VERSION ""

NS_ :

BS_:

BU_: SensoricSolutionsOMSRace SensoricSolutionsOMS7

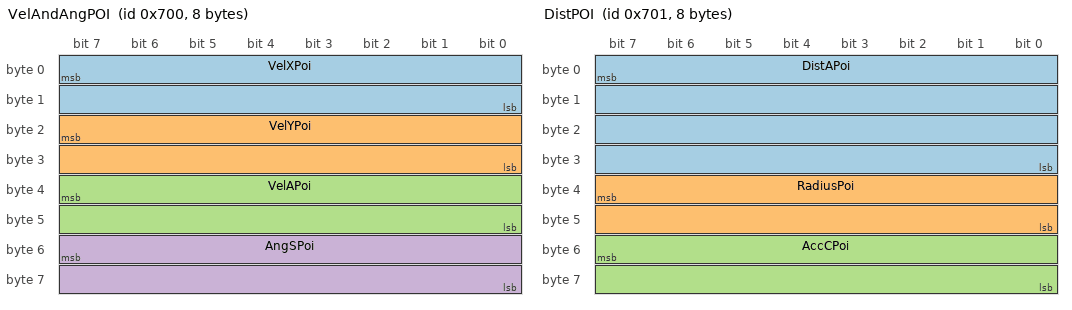
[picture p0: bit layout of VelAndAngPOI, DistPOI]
BO_ 1792 VelAndAngPOI: 8 SensoricSolutionsOMSRace
 SG_ VelXPoi : 7|16@0- (0.02,0) [-450|450] "km/h"  SensoricSolutionsOMSRace
 SG_ VelYPoi : 23|16@0- (0.02,0) [-100|100] "km/h"  SensoricSolutionsOMSRace
 SG_ VelAPoi : 39|16@0- (0.02,0) [0|450] "km/h"  SensoricSolutionsOMSRace
 SG_ AngSPoi : 55|16@0- (0.003,0) [-40|40] "deg"  SensoricSolutionsOMSRace

BO_ 1793 DistPOI: 8 SensoricSolutionsOMSRace
 SG_ DistAPoi : 7|32@0- (0.001,0) [-2000000|2000000] "m"  SensoricSolutionsOMSRace
 SG_ RadiusPoi : 39|16@0- (0.01,0) [-327.68|327.67] "m"  SensoricSolutionsOMSRace
 SG_ AccCPoi : 55|16@0- (0.02,0) [-200|200] "m/s/s"  SensoricSolutionsOMSRace

BO_ 1794 PitchAndRoll: 4 SensoricSolutionsOMSRace
 SG_ Roll : 7|16@0- (0.003,0) [-90|90] "deg"  SensoricSolutionsOMSRace
 SG_ Pitch : 23|16@0- (0.003,0) [-90|90] "deg"  SensoricSolutionsOMSRace

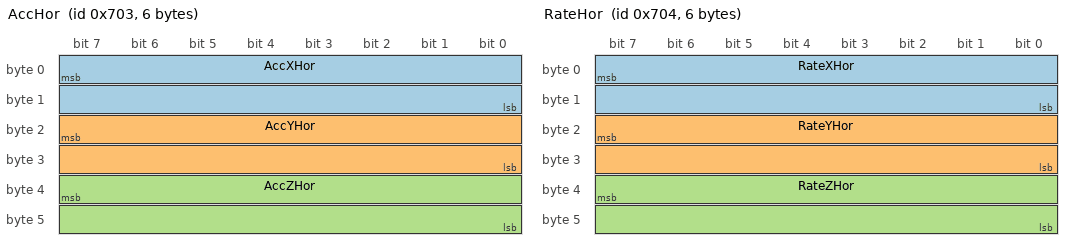
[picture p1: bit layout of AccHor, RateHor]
BO_ 1795 AccHor: 6 SensoricSolutionsOMSRace
 SG_ AccXHor : 7|16@0- (0.02,0) [-200|200] "m/s/s"  SensoricSolutionsOMSRace
 SG_ AccYHor : 23|16@0- (0.02,0) [-200|200] "m/s/s"  SensoricSolutionsOMSRace
 SG_ AccZHor : 39|16@0- (0.02,0) [-200|200] "m/s/s"  SensoricSolutionsOMSRace

BO_ 1796 RateHor: 6 SensoricSolutionsOMSRace
 SG_ RateXHor : 7|16@0- (0.02,0) [-500|500] "deg/s"  SensoricSolutionsOMSRace
 SG_ RateYHor : 23|16@0- (0.02,0) [-500|500] "deg/s"  SensoricSolutionsOMSRace
 SG_ RateZHor : 39|16@0- (0.02,0) [-500|500] "deg/s"  SensoricSolutionsOMSRace

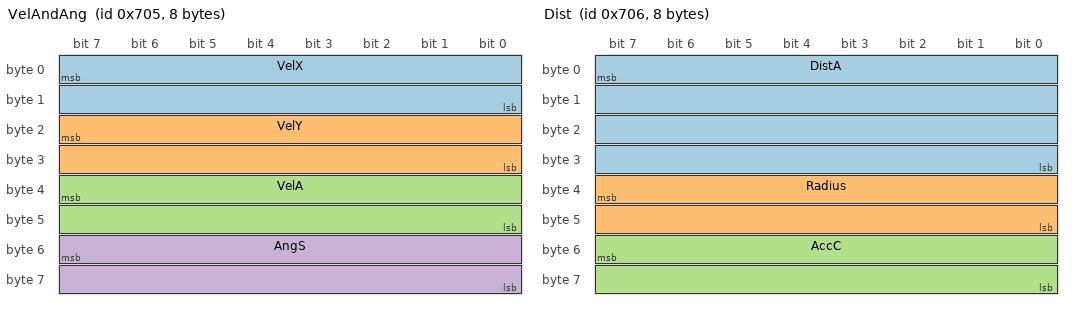
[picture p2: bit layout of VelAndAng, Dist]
BO_ 1797 VelAndAng: 8 SensoricSolutionsOMSRace
 SG_ VelX : 7|16@0- (0.02,0) [-450|450] "km/h"  SensoricSolutionsOMSRace
 SG_ VelY : 23|16@0- (0.02,0) [-100|100] "km/h"  SensoricSolutionsOMSRace
 SG_ VelA : 39|16@0- (0.02,0) [0|450] "km/h"  SensoricSolutionsOMSRace
 SG_ AngS : 55|16@0- (0.003,0) [-40|40] "deg"  SensoricSolutionsOMSRace

BO_ 1798 Dist: 8 SensoricSolutionsOMSRace
 SG_ DistA : 7|32@0- (0.001,0) [-2000000|2000000] "m"  SensoricSolutionsOMSRace
 SG_ Radius : 39|16@0- (0.01,0) [-327.68|327.67] "m"  SensoricSolutionsOMSRace
 SG_ AccC : 55|16@0- (0.02,0) [-200|200] "m/s/s"  SensoricSolutionsOMSRace

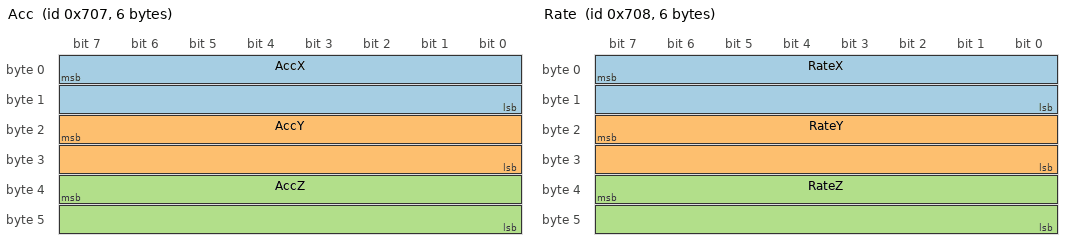
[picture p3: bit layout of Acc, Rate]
BO_ 1799 Acc: 6 SensoricSolutionsOMSRace
 SG_ AccX : 7|16@0- (0.02,0) [-200|200] "m/s/s"  SensoricSolutionsOMSRace
 SG_ AccY : 23|16@0- (0.02,0) [-200|200] "m/s/s"  SensoricSolutionsOMSRace
 SG_ AccZ : 39|16@0- (0.02,0) [-200|200] "m/s/s"  SensoricSolutionsOMSRace

BO_ 1800 Rate: 6 SensoricSolutionsOMSRace
 SG_ RateX : 7|16@0- (0.02,0) [-500|500] "deg/s"  SensoricSolutionsOMSRace
 SG_ RateY : 23|16@0- (0.02,0) [-500|500] "deg/s"  SensoricSolutionsOMSRace
 SG_ RateZ : 39|16@0- (0.02,0) [-500|500] "deg/s"  SensoricSolutionsOMSRace

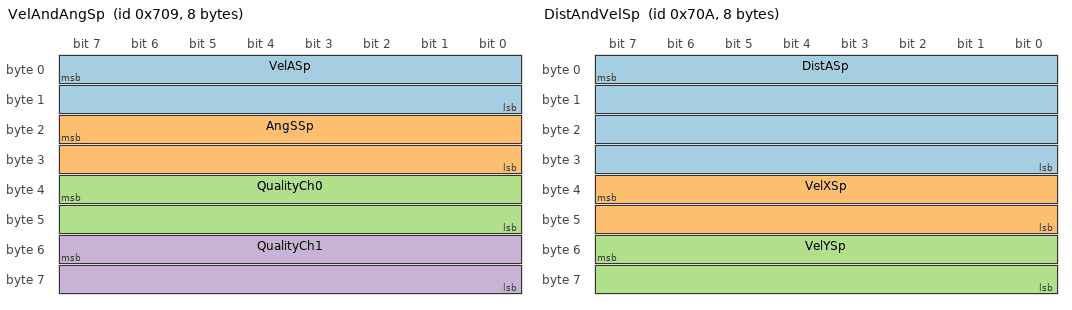
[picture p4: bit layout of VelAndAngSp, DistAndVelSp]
BO_ 1801 VelAndAngSp: 8 SensoricSolutionsOMSRace
 SG_ VelASp : 7|16@0- (0.02,0) [0|450] "km/h"  SensoricSolutionsOMSRace
 SG_ AngSSp : 23|16@0- (0.003,0) [-40|40] "deg"  SensoricSolutionsOMSRace
 SG_ QualityCh0 : 39|16@0+ (1,0) [0|65535] ""  SensoricSolutionsOMSRace
 SG_ QualityCh1 : 55|16@0+ (1,0) [0|65535] ""  SensoricSolutionsOMSRace

BO_ 1802 DistAndVelSp: 8 SensoricSolutionsOMSRace
 SG_ DistASp : 7|32@0- (0.001,0) [-2000000|2000000] "m"  SensoricSolutionsOMSRace
 SG_ VelXSp : 39|16@0- (0.02,0) [-450|450] "km/h"  SensoricSolutionsOMSRace
 SG_ VelYSp : 55|16@0- (0.02,0) [-100|100] "km/h"  SensoricSolutionsOMSRace

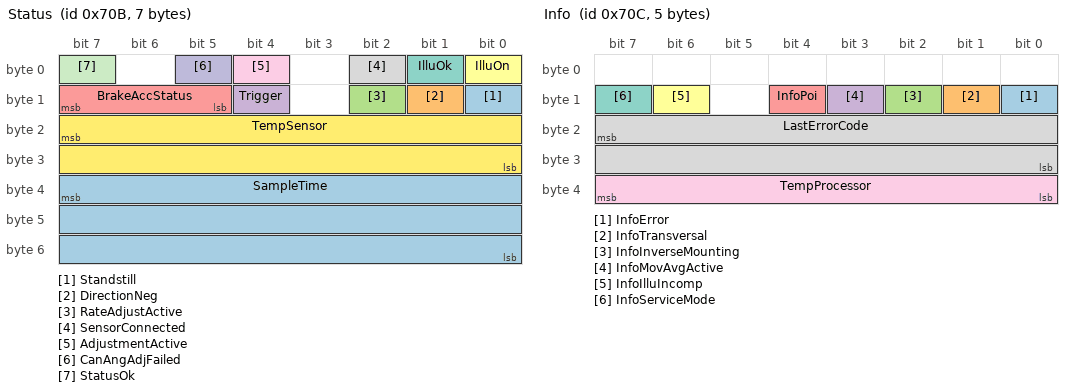
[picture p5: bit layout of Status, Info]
BO_ 1803 Status: 7 SensoricSolutionsOMSRace
 SG_ Standstill : 8|1@0+ (1,0) [0|1] ""  SensoricSolutionsOMSRace
 SG_ DirectionNeg : 9|1@0+ (1,0) [0|1] ""  SensoricSolutionsOMSRace
 SG_ RateAdjustActive : 10|1@0+ (1,0) [0|1] ""  SensoricSolutionsOMSRace
 SG_ Trigger : 12|1@0+ (1,0) [0|1] ""  SensoricSolutionsOMSRace
 SG_ BrakeAccStatus : 15|3@0+ (1,0) [0|5] ""  SensoricSolutionsOMS7
 SG_ IlluOn : 0|1@0+ (1,0) [0|1] ""  SensoricSolutionsOMSRace
 SG_ IlluOk : 1|1@0+ (1,0) [0|1] ""  SensoricSolutionsOMSRace
 SG_ SensorConnected : 2|1@0+ (1,0) [0|1] ""  SensoricSolutionsOMSRace
 SG_ AdjustmentActive : 4|1@0+ (1,0) [0|1] ""  SensoricSolutionsOMSRace
 SG_ CanAngAdjFailed : 5|1@0+ (1,0) [0|1] ""  SensoricSolutionsOMSRace
 SG_ StatusOk : 7|1@0+ (1,0) [0|1] ""  SensoricSolutionsOMSRace
 SG_ TempSensor : 23|16@0- (0.1,0) [-20|85] "C"  SensoricSolutionsOMSRace
 SG_ SampleTime : 39|24@0+ (0.001,0) [0|16777.215] "s"  SensoricSolutionsOMSRace

BO_ 1804 Info: 5 SensoricSolutionsOMSRace
 SG_ InfoError : 8|1@0+ (1,0) [0|1] ""  SensoricSolutionsOMSRace
 SG_ InfoTransversal : 9|1@0+ (1,0) [0|1] ""  SensoricSolutionsOMSRace
 SG_ InfoInverseMounting : 10|1@0+ (1,0) [0|1] ""  SensoricSolutionsOMSRace
 SG_ InfoMovAvgActive : 11|1@0+ (1,0) [0|1] ""  SensoricSolutionsOMSRace
 SG_ InfoPoi : 12|1@0+ (1,0) [0|1] ""  SensoricSolutionsOMSRace
 SG_ InfoIlluIncomp : 14|1@0+ (1,0) [0|1] ""  SensoricSolutionsOMSRace
 SG_ InfoServiceMode : 15|1@0+ (1,0) [0|1] ""  SensoricSolutionsOMSRace
 SG_ LastErrorCode : 23|16@0+ (1,0) [0|65535] ""  SensoricSolutionsOMSRace
 SG_ TempProcessor : 39|8@0- (1,0) [-128|127] "C"  SensoricSolutionsOMSRace

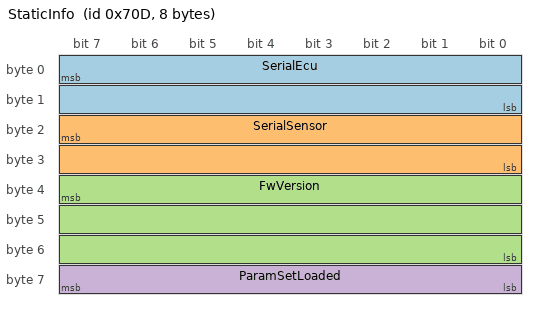
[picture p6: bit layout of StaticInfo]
BO_ 1805 StaticInfo: 8 SensoricSolutionsOMSRace
 SG_ SerialEcu : 7|16@0+ (1,0) [0|65535] ""  SensoricSolutionsOMSRace
 SG_ SerialSensor : 23|16@0+ (1,0) [0|65535] ""  SensoricSolutionsOMSRace
 SG_ FwVersion : 39|24@0+ (1,0) [0|16777215] ""  SensoricSolutionsOMSRace
 SG_ ParamSetLoaded : 63|8@0+ (1,0) [0|255] ""  SensoricSolutionsOMSRace

BA_DEF_ BO_  "GenMsgCycleTimeus" INT 100 60000000;
BA_DEF_DEF_  "GenMsgCycleTimeus" 1000;
BA_ "GenMsgCycleTimeus" BO_ 1792 8000;
BA_ "GenMsgCycleTimeus" BO_ 1793 8000;
BA_ "GenMsgCycleTimeus" BO_ 1794 8000;
BA_ "GenMsgCycleTimeus" BO_ 1795 8000;
BA_ "GenMsgCycleTimeus" BO_ 1796 8000;
BA_ "GenMsgCycleTimeus" BO_ 1797 8000;
BA_ "GenMsgCycleTimeus" BO_ 1798 8000;
BA_ "GenMsgCycleTimeus" BO_ 1799 8000;
BA_ "GenMsgCycleTimeus" BO_ 1800 8000;
BA_ "GenMsgCycleTimeus" BO_ 1801 8000;
BA_ "GenMsgCycleTimeus" BO_ 1802 8000;
BA_ "GenMsgCycleTimeus" BO_ 1803 8000;
BA_ "GenMsgCycleTimeus" BO_ 1804 1000000;
BA_ "GenMsgCycleTimeus" BO_ 1805 1000000;
